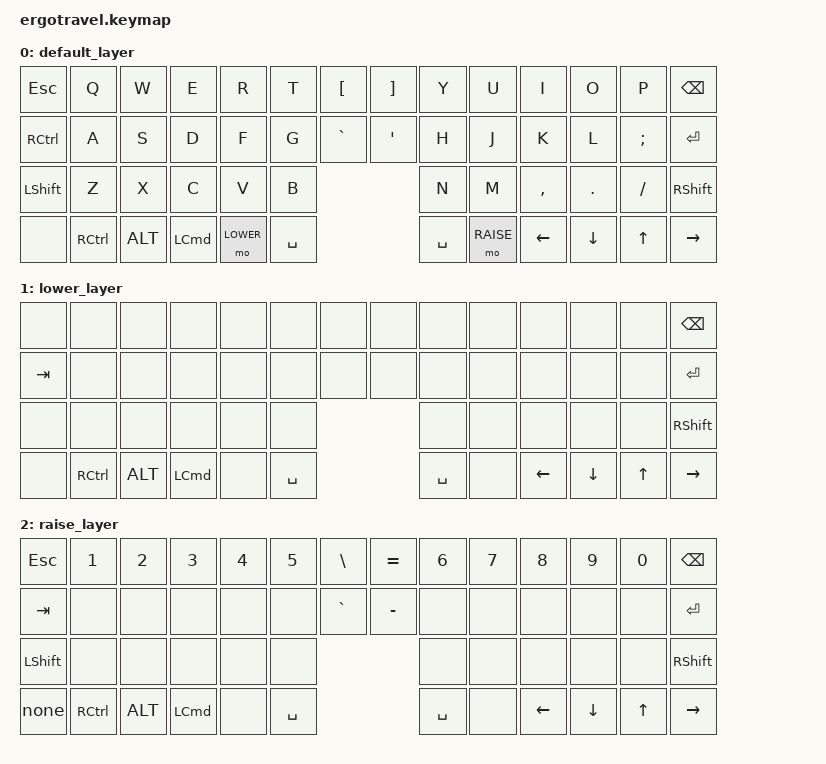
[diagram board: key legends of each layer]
#include <behaviors.dtsi>
#include <dt-bindings/zmk/keys.h>

#define DEFAULT 0
#define LOWER   1
#define RAISE   2

/ {
    keymap {
        compatible = "zmk,keymap";

        default_layer {
// --------------------------------------------------------------------------------------------------------------------------------------------------------------------
// |   ESC   |    Q    |    W    |    E    |    R    |    T    |    {    |  |    }    |    Y    |    U    |    I    |    O    |    P    |  BSPC   |
// |   CTRL  |    A    |    S    |    D    |    F    |    G    |    `    |  |    '    |    H    |    J    |    K    |    L    |    ;    |  ENTER  |
// |  SHIFT  |    Z    |    X    |    C    |    V    |    B    |                      |    N    |    M    |    ,    |    .    |    /    |  SHIFT  |
// |         |  CTRL   |  OPTION |   CMD   |  LOWER  |  SPACE  |                      |  SPACE  |  RAISE  |   LEFT  |  DOWN   |   UP    |  RIGHT  |
            bindings = <
    &kp ESC    &kp Q     &kp W    &kp E     &kp R     &kp T     &kp LBKT     &kp RBKT  &kp Y     &kp U     &kp I     &kp O     &kp P     &kp BSPC
    &kp RCTRL  &kp A     &kp S    &kp D     &kp F     &kp G     &kp GRAVE    &kp SQT   &kp H     &kp J     &kp K     &kp L     &kp SEMI  &kp ENTER
    &kp LSHIFT &kp Z     &kp X    &kp C     &kp V     &kp B                            &kp N     &kp M     &kp COMMA &kp DOT   &kp FSLH  &kp RSHIFT
    &none      &kp RCTRL &kp ALT  &kp LCMD  &mo LOWER &kp SPACE                        &kp SPACE &mo RAISE &kp LEFT  &kp DOWN  &kp UP    &kp RIGHT
            >;
        };

        lower_layer {
            bindings = <
    &none     &none     &none    &none     &none     &none     &none        &none     &none     &none     &none     &none     &none     &kp BSPC
    &kp TAB   &none     &none    &none     &none     &none     &none        &none     &none     &none     &none     &none     &none     &kp ENTER
    &none     &none     &none    &none     &none     &none                            &none     &none     &none     &none     &none     &kp RSHIFT
    &none     &kp RCTRL &kp ALT  &kp LCMD  &none     &kp SPACE                        &kp SPACE &none     &kp LEFT  &kp DOWN  &kp UP    &kp RIGHT
            >;            
        };

        raise_layer {
            bindings = <
    &kp ESC    &kp N1    &kp N2   &kp N3    &kp N4    &kp N5    &kp BSLH     &kp EQUAL &kp N6    &kp N7    &kp N8    &kp N9    &kp N0    &kp BSPC
    &kp TAB    &none     &none    &none     &none     &none     &kp GRAVE    &kp MINUS &none     &none     &none     &none     &none     &kp ENTER
    &kp LSHIFT &none     &none    &none     &none     &none                            &none     &none     &none     &none     &none     &kp RSHIFT
    $none      &kp RCTRL &kp ALT  &kp LCMD  &none     &kp SPACE                        &kp SPACE &none     &kp LEFT  &kp DOWN  &kp UP    &kp RIGHT
            >;            
        };
    };
};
